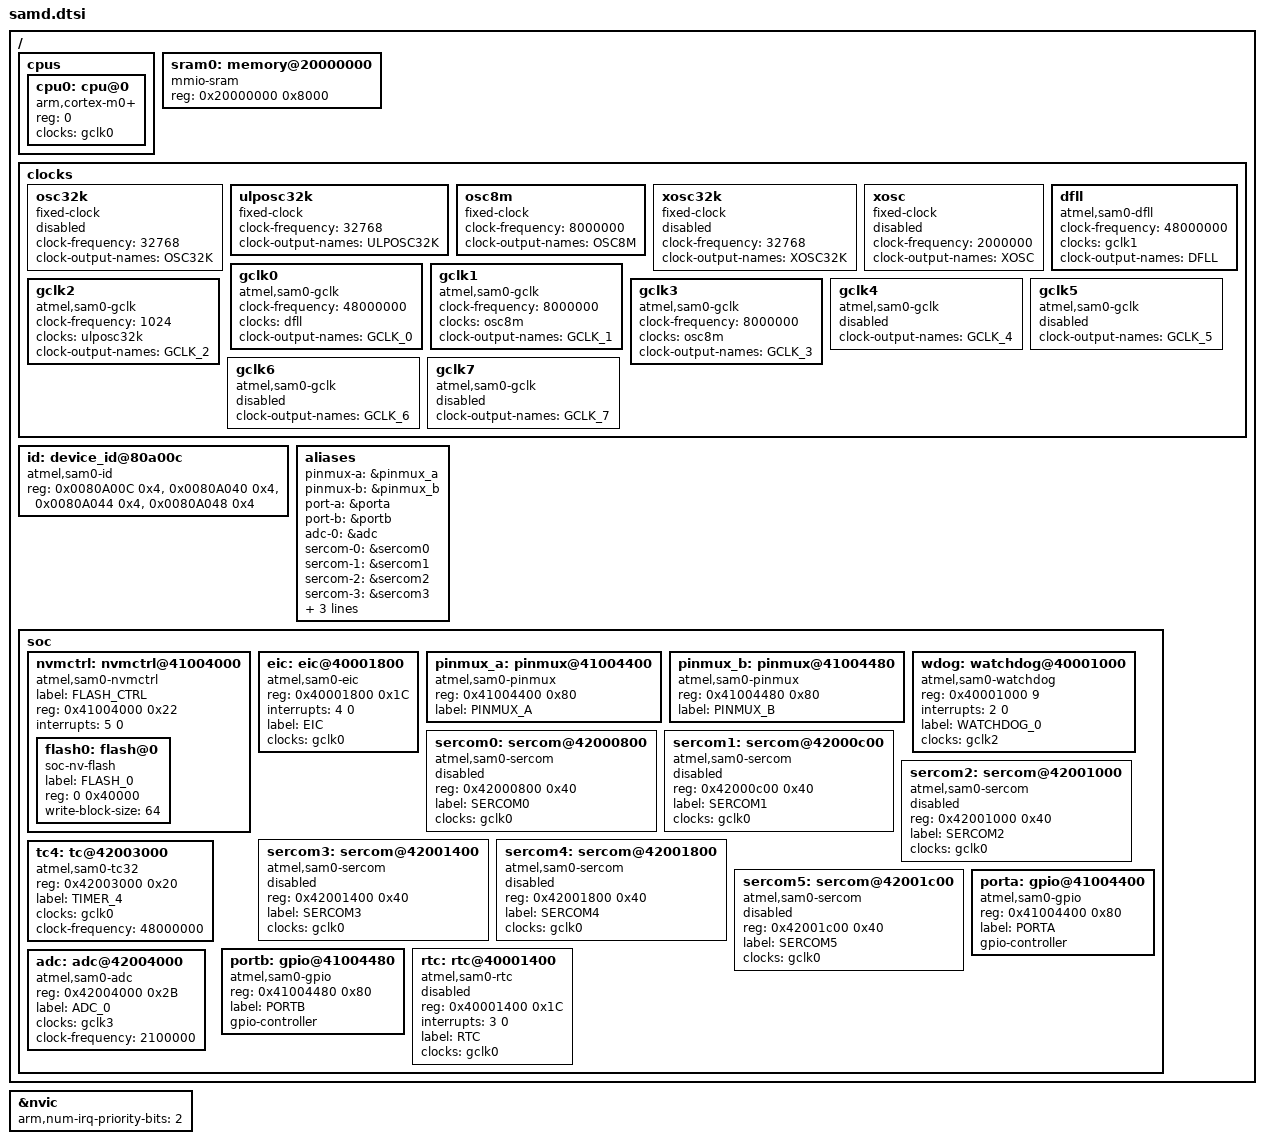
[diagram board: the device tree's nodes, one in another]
/*
 * Copyright (c) 2017 Google LLC.
 *
 * SPDX-License-Identifier: Apache-2.0
 */

#include <arm/armv6-m.dtsi>
#include <dt-bindings/gpio/gpio.h>
#include <dt-bindings/i2c/i2c.h>

/ {
	cpus {
		#address-cells = <1>;
		#size-cells = <0>;

		cpu0: cpu@0 {
			device_type = "cpu";
			compatible = "arm,cortex-m0+";
			reg = <0>;
			clocks = <&gclk0>;
		};
	};

	sram0: memory@20000000 {
		device_type = "memory";
		compatible = "mmio-sram";
		reg = <0x20000000 0x8000>;
	};

	clocks {
		#address-cells = <0>;

		osc32k: osc32k {
			compatible = "fixed-clock";
			clock-frequency = <32768>;
			#clock-cells = <0>;
			status = "disabled";
			clock-output-names = "OSC32K";
		};

		ulposc32k: ulposc32k {
			compatible = "fixed-clock";
			clock-frequency = <32768>;
			#clock-cells = <0>;
			clock-output-names = "ULPOSC32K";
		};

		osc8m: osc8m {
			compatible = "fixed-clock";
			clock-frequency = <8000000>;
			#clock-cells = <0>;
			clock-output-names = "OSC8M";
		};

		xosc32k: xosc32k {
			compatible = "fixed-clock";
			clock-frequency = <32768>;
			#clock-cells = <0>;
			status = "disabled";
			clock-output-names = "XOSC32K";
		};

		xosc: xosc {
			compatible = "fixed-clock";
			#clock-cells = <0>;
			clock-frequency = <2000000>;
			status = "disabled";
			clock-output-names = "XOSC";
		};

		dfll: dfll {
			compatible = "atmel,sam0-dfll";
			clock-frequency = <48000000>;
			clocks = <&gclk1>;
			#clock-cells = <0>;
			clock-output-names = "DFLL";
		};

		gclk0: gclk0 {
			compatible = "atmel,sam0-gclk";
			clock-frequency = <48000000>;
			clocks = <&dfll>;
			#clock-cells = <0>;
			clock-output-names = "GCLK_0";
		};

		gclk1: gclk1 {
			compatible = "atmel,sam0-gclk";
			clock-frequency = <8000000>;
			clocks = <&osc8m>;
			#clock-cells = <0>;
			clock-output-names = "GCLK_1";
		};

		gclk2: gclk2 {
			compatible = "atmel,sam0-gclk";
			clock-frequency = <1024>;
			clocks = <&ulposc32k>;
			#clock-cells = <0>;
			clock-output-names = "GCLK_2";
		};

		gclk3: gclk3 {
			compatible = "atmel,sam0-gclk";
			clock-frequency = <8000000>;
			clocks = <&osc8m>;
			#clock-cells = <0>;
			clock-output-names = "GCLK_3";
		};

		gclk4: gclk4 {
			compatible = "atmel,sam0-gclk";
			status = "disabled";
			#clock-cells = <0>;
			clock-output-names = "GCLK_4";
		};

		gclk5: gclk5 {
			compatible = "atmel,sam0-gclk";
			status = "disabled";
			#clock-cells = <0>;
			clock-output-names = "GCLK_5";
		};

		gclk6: gclk6 {
			compatible = "atmel,sam0-gclk";
			status = "disabled";
			#clock-cells = <0>;
			clock-output-names = "GCLK_6";
		};

		gclk7: gclk7 {
			compatible = "atmel,sam0-gclk";
			status = "disabled";
			#clock-cells = <0>;
			clock-output-names = "GCLK_7";
		};
	};

	id: device_id@80a00c {
		compatible = "atmel,sam0-id";
		reg =	<0x0080A00C 0x4>,
			<0x0080A040 0x4>,
			<0x0080A044 0x4>,
			<0x0080A048 0x4>;
	};

	aliases {
		pinmux-a = &pinmux_a;
		pinmux-b = &pinmux_b;
		port-a = &porta;
		port-b = &portb;
		adc-0 = &adc;

		sercom-0 = &sercom0;
		sercom-1 = &sercom1;
		sercom-2 = &sercom2;
		sercom-3 = &sercom3;
		sercom-4 = &sercom4;
		sercom-5 = &sercom5;

		tc-4 = &tc4;
	};

	soc {
		nvmctrl: nvmctrl@41004000  {
			compatible = "atmel,sam0-nvmctrl";
			label = "FLASH_CTRL";
			reg = <0x41004000 0x22>;
			interrupts = <5 0>;

			#address-cells = <1>;
			#size-cells = <1>;

			flash0: flash@0 {
				compatible = "soc-nv-flash";
				label = "FLASH_0";
				reg = <0 0x40000>;
				write-block-size = <64>;
			};
		};

		eic: eic@40001800 {
			compatible = "atmel,sam0-eic";
			reg = <0x40001800 0x1C>;
			interrupts = <4 0>;
			label = "EIC";
			clocks = <&gclk0>;
		};

		pinmux_a: pinmux@41004400 {
			compatible = "atmel,sam0-pinmux";
			reg = <0x41004400 0x80>;
			label = "PINMUX_A";
		};

		pinmux_b: pinmux@41004480 {
			compatible = "atmel,sam0-pinmux";
			reg = <0x41004480 0x80>;
			label = "PINMUX_B";
		};

		wdog: watchdog@40001000 {
			compatible = "atmel,sam0-watchdog";
			reg = <0x40001000 9>;
			interrupts = <2 0>;
			label = "WATCHDOG_0";
			clocks = <&gclk2>;
		};

		sercom0: sercom@42000800 {
			compatible = "atmel,sam0-sercom";
			reg = <0x42000800 0x40>;
			status = "disabled";
			label = "SERCOM0";
			clocks = <&gclk0>;
		};

		sercom1: sercom@42000c00 {
			compatible = "atmel,sam0-sercom";
			reg = <0x42000c00 0x40>;
			status = "disabled";
			label = "SERCOM1";
			clocks = <&gclk0>;
		};

		sercom2: sercom@42001000 {
			compatible = "atmel,sam0-sercom";
			reg = <0x42001000 0x40>;
			status = "disabled";
			label = "SERCOM2";
			clocks = <&gclk0>;
		};

		sercom3: sercom@42001400 {
			compatible = "atmel,sam0-sercom";
			reg = <0x42001400 0x40>;
			status = "disabled";
			label = "SERCOM3";
			clocks = <&gclk0>;
		};

		sercom4: sercom@42001800 {
			compatible = "atmel,sam0-sercom";
			reg = <0x42001800 0x40>;
			status = "disabled";
			label = "SERCOM4";
			clocks = <&gclk0>;
		};

		sercom5: sercom@42001c00 {
			compatible = "atmel,sam0-sercom";
			reg = <0x42001c00 0x40>;
			status = "disabled";
			label = "SERCOM5";
			clocks = <&gclk0>;
		};

		tc4: tc@42003000 {
			compatible = "atmel,sam0-tc32";
			reg = <0x42003000 0x20>;
			label = "TIMER_4";
			clocks = <&gclk0>;
			clock-frequency = <48000000>;
		};

		porta: gpio@41004400 {
			compatible = "atmel,sam0-gpio";
			reg = <0x41004400 0x80>;
			label = "PORTA";
			gpio-controller;
			#gpio-cells = <2>;
		};

		portb: gpio@41004480 {
			compatible = "atmel,sam0-gpio";
			reg = <0x41004480 0x80>;
			label = "PORTB";
			gpio-controller;
			#gpio-cells = <2>;
		};

		rtc: rtc@40001400 {
			compatible = "atmel,sam0-rtc";
			reg = <0x40001400 0x1C>;
			interrupts = <3 0>;
			status = "disabled";
			label = "RTC";
			clocks = <&gclk0>;
		};

		adc: adc@42004000 {
			compatible = "atmel,sam0-adc";
			reg = <0x42004000 0x2B>;
			label = "ADC_0";
			clocks = <&gclk3>;
			clock-frequency = <2100000>;
		};
	};
};

&nvic {
	arm,num-irq-priority-bits = <2>;
};
